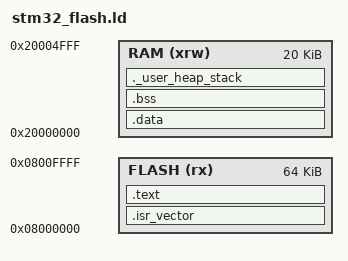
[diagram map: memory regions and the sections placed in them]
/****************************************************************************
 ** stm32_flash.ld
 ***************************************************************************/

/* Entry Point */
ENTRY(Reset_Handler)

/* Highest address of the user mode stack */
//_estack = 0x20002800;    /* end of 10K RAM */
_estack = 0x20005000;    /* end of 20K RAM */

/* Generate a link error if heap and stack don't fit into RAM */
_Min_Heap_Size = 0x400;  /* required amount of heap  */
_Min_Stack_Size = 0x400; /* required amount of stack */

/* Specify the memory areas */
MEMORY
{
  FLASH (rx)      : ORIGIN = 0x08000000, LENGTH = 64K
  RAM (xrw)       : ORIGIN = 0x20000000, LENGTH = 20K
}

/* Define output sections */
SECTIONS
{
  /* The startup code goes first into FLASH */
  .isr_vector :
  {
    . = ALIGN(1);
    KEEP(*(.isr_vector)) /* Startup code */
    . = ALIGN(1);
  } >FLASH

  /* The program code and other data goes into FLASH */
  .text :
  {
    . = ALIGN(4);
    *(.text)           /* .text sections (code) */
    *(.text*)          /* .text* sections (code) */
    *(.rodata)         /* .rodata sections (constants, strings, etc.) */
    *(.rodata*)        /* .rodata* sections (constants, strings, etc.) */
    . = ALIGN(4);
    _etext = .;        /* define a global symbols at end of code */
  } >FLASH


  /* used by the startup to initialize data */
  _sidata = .;

  /* Initialized data sections goes into RAM, load LMA copy after code */
  .data : AT ( _sidata )
  {
    . = ALIGN(4);
    _sdata = .;        /* create a global symbol at data start */
    *(.data)           /* .data sections */
    *(.data*)          /* .data* sections */
    . = ALIGN(4);
    _edata = .;        /* define a global symbol at data end */
  } >RAM

  /* Uninitialized data section */
  . = ALIGN(4);
  .bss :
  {
    /* This is used by the startup in order to initialize the .bss secion */
    _sbss = .;         /* define a global symbol at bss start */
    __bss_start__ = _sbss;
    *(.bss)
    *(.bss*)
    *(COMMON)
    . = ALIGN(4);
    _ebss = .;         /* define a global symbol at bss end */
    __bss_end__ = _ebss;
  } >RAM

  PROVIDE ( end = _ebss );
  PROVIDE ( _end = _ebss );

  /* User_heap_stack section, used to check that there is enough RAM left */
  ._user_heap_stack :
  {
    . = ALIGN(4);
    . = . + _Min_Heap_Size;
    . = . + _Min_Stack_Size;
    . = ALIGN(4);
  } >RAM

}
